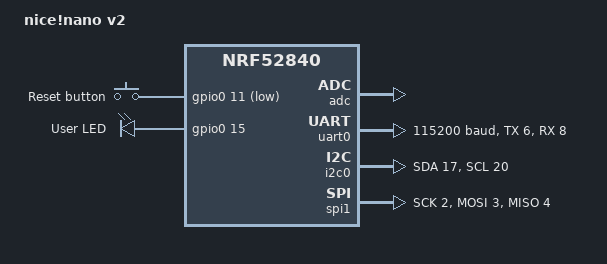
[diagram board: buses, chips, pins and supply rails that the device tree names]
/dts-v1/;
#include <nordic/nrf52840_qiaa.dtsi>

/ {
    model = "nice!nano v2";
    compatible = "nice,nano-v2";

    chosen {
        zephyr,console = &uart0;
        zephyr,shell-uart = &uart0;
        zephyr,uart-mcumgr = &uart0;
        zephyr,bt-mon-uart = &uart0;
        zephyr,bt-c2h-uart = &uart0;
        zephyr,sram = &sram0;
        zephyr,flash = &flash0;
        zephyr,code-partition = &slot0_partition;
    };

    /* Buttons */
    buttons {
        compatible = "gpio-keys";
        button0: button_0 {
            gpios = <&gpio0 11 GPIO_ACTIVE_LOW>;
            label = "Reset button";
        };
    };

    /* LEDs */
    leds {
        compatible = "gpio-leds";
        led0: led_0 {
            gpios = <&gpio0 15 GPIO_ACTIVE_HIGH>;
            label = "User LED";
        };
    };
};

&adc {
    status = "okay";
};

&gpiote {
    status = "okay";
};

&gpio0 {
    status = "okay";
};

&gpio1 {
    status = "okay";
};

&uart0 {
    compatible = "nordic,nrf-uart";
    status = "okay";
    current-speed = <115200>;
    tx-pin = <6>;
    rx-pin = <8>;
};

&i2c0 {
    status = "okay";
    sda-pin = <17>;
    scl-pin = <20>;
};

&spi1 {
    status = "okay";
    sck-pin = <2>;
    mosi-pin = <3>;
    miso-pin = <4>;
};

&flash0 {
    partitions {
        compatible = "fixed-partitions";
        #address-cells = <1>;
        #size-cells = <1>;

        boot_partition: partition@0 {
            label = "mcuboot";
            reg = <0x00000000 0x0000C000>;
        };
        slot0_partition: partition@c000 {
            label = "image-0";
            reg = <0x0000C000 0x00067000>;
        };
        slot1_partition: partition@73000 {
            label = "image-1";
            reg = <0x00073000 0x00067000>;
        };
        storage_partition: partition@da000 {
            label = "storage";
            reg = <0x000da000 0x00026000>;
        };
    };
};
